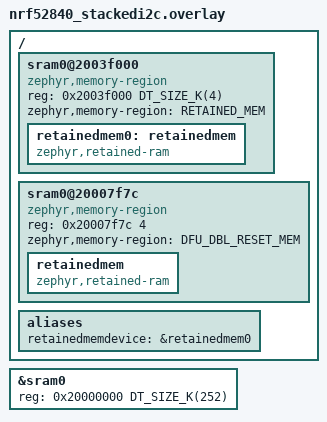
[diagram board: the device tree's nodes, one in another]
/ {
	sram0@2003f000 {
		compatible = "zephyr,memory-region", "mmio-sram";
		reg = <0x2003f000 DT_SIZE_K(4)>;
		zephyr,memory-region = "RETAINED_MEM";
		status = "okay";

		retainedmem0: retainedmem {
			compatible = "zephyr,retained-ram";
			status = "okay";
		};
	};

	sram0@20007f7c {
		compatible = "zephyr,memory-region", "mmio-sram";
		reg = <0x20007f7c 4>;
		zephyr,memory-region = "DFU_DBL_RESET_MEM";
		status = "okay";

		retainedmem {
			compatible = "zephyr,retained-ram";
			status = "okay";
		};
	};

	aliases {
		retainedmemdevice = &retainedmem0;
	};
};

&sram0 {
	/* Shrink SRAM size to avoid overlap with retained memory region */
	reg = <0x20000000 DT_SIZE_K(252)>;
};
